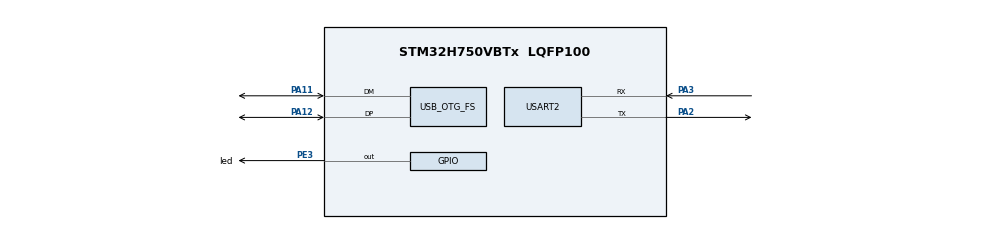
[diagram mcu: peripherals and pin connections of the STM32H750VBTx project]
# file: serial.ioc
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CORTEX_M7.default_mode_Activation=1
Dma.Request0=USART2_RX
Dma.Request1=USART2_TX
Dma.USART2_RX.0.Direction=DMA_PERIPH_TO_MEMORY
Dma.USART2_RX.0.EventEnable=DISABLE
Dma.USART2_RX.0.FIFOMode=DMA_FIFOMODE_DISABLE
Dma.USART2_RX.0.Instance=DMA1_Stream0
Dma.USART2_RX.0.MemDataAlignment=DMA_MDATAALIGN_BYTE
Dma.USART2_RX.0.MemInc=DMA_MINC_ENABLE
Dma.USART2_RX.0.Mode=DMA_NORMAL
Dma.USART2_RX.0.PeriphDataAlignment=DMA_PDATAALIGN_BYTE
Dma.USART2_RX.0.PeriphInc=DMA_PINC_DISABLE
Dma.USART2_RX.0.Polarity=HAL_DMAMUX_REQ_GEN_RISING
Dma.USART2_RX.0.Priority=DMA_PRIORITY_LOW
Dma.USART2_RX.0.RequestNumber=1
Dma.USART2_RX.0.SignalID=NONE
Dma.USART2_RX.0.SyncEnable=DISABLE
Dma.USART2_RX.0.SyncPolarity=HAL_DMAMUX_SYNC_NO_EVENT
Dma.USART2_RX.0.SyncRequestNumber=1
Dma.USART2_RX.0.SyncSignalID=NONE
Dma.USART2_TX.1.Direction=DMA_MEMORY_TO_PERIPH
Dma.USART2_TX.1.EventEnable=DISABLE
Dma.USART2_TX.1.FIFOMode=DMA_FIFOMODE_DISABLE
Dma.USART2_TX.1.Instance=DMA1_Stream1
Dma.USART2_TX.1.MemDataAlignment=DMA_MDATAALIGN_BYTE
Dma.USART2_TX.1.MemInc=DMA_MINC_ENABLE
Dma.USART2_TX.1.Mode=DMA_NORMAL
Dma.USART2_TX.1.PeriphDataAlignment=DMA_PDATAALIGN_BYTE
Dma.USART2_TX.1.PeriphInc=DMA_PINC_DISABLE
Dma.USART2_TX.1.Polarity=HAL_DMAMUX_REQ_GEN_RISING
Dma.USART2_TX.1.Priority=DMA_PRIORITY_LOW
Dma.USART2_TX.1.RequestNumber=1
Dma.USART2_TX.1.SignalID=NONE
Dma.USART2_TX.1.SyncEnable=DISABLE
Dma.USART2_TX.1.SyncPolarity=HAL_DMAMUX_SYNC_NO_EVENT
Dma.USART2_TX.1.SyncRequestNumber=1
Dma.USART2_TX.1.SyncSignalID=NONE
Mcu.Family=STM32H7
Mcu.Name=STM32H750VBTx
Mcu.Package=LQFP100
NVIC.DMA1_Stream0_IRQn=true\:0\:0\:false\:false\:true\:false\:true\:true
NVIC.DMA1_Stream1_IRQn=true\:0\:0\:false\:false\:true\:false\:true\:true
NVIC.OTG_FS_IRQn=true\:0\:0\:false\:false\:true\:false\:true\:true
NVIC.PriorityGroup=NVIC_PRIORITYGROUP_4
NVIC.USART2_IRQn=true\:0\:0\:false\:false\:true\:true\:true\:true
PA11.Mode=Device_Only
PA11.Signal=USB_OTG_FS_DM
PA12.Mode=Device_Only
PA12.Signal=USB_OTG_FS_DP
PA2.Mode=Asynchronous
PA2.Signal=USART2_TX
PA3.Mode=Asynchronous
PA3.Signal=USART2_RX
PE3.GPIO_Label=led
PE3.PinState=GPIO_PIN_SET
PE3.Signal=GPIO_Output
PH0-OSC_IN\ (PH0).Mode=HSE-External-Oscillator
PH0-OSC_IN\ (PH0).Signal=RCC_OSC_IN
PH1-OSC_OUT\ (PH1).Mode=HSE-External-Oscillator
PH1-OSC_OUT\ (PH1).Signal=RCC_OSC_OUT
ProjectManager.HeapSize=0x200
ProjectManager.StackSize=0x400
ProjectManager.TargetToolchain=STM32CubeIDE
RCC.ADCFreq_Value=50390625
RCC.APB1Freq_Value=120000000
RCC.APB2Freq_Value=120000000
RCC.APB3Freq_Value=120000000
RCC.APB4Freq_Value=120000000
RCC.CortexFreq_Value=120000000
RCC.DIVM1=5
RCC.DIVN1=48
RCC.HCLKFreq_Value=120000000
RCC.PLL2FRACN=0
RCC.PLL3FRACN=0
RCC.PLLFRACN=0
RCC.PLLSourceVirtual=RCC_PLLSOURCE_HSE
RCC.SYSCLKFreq_VALUE=120000000
RCC.SYSCLKSource=RCC_SYSCLKSOURCE_PLLCLK
RCC.USART234578CLockSelection=RCC_USART234578CLKSOURCE_CSI
RCC.USBCLockSelection=RCC_USBCLKSOURCE_HSI48
RCC.USBFreq_Value=48000000
USART2.VirtualMode-Asynchronous=VM_ASYNC
USB_DEVICE.CLASS_NAME_FS=CDC
USB_DEVICE.VirtualMode-CDC_FS=Cdc
USB_DEVICE.VirtualModeFS=Cdc_FS
USB_OTG_FS.VirtualMode=Device_Only
VP_MEMORYMAP_VS_MEMORYMAP.Mode=CurAppReg
VP_USB_DEVICE_VS_USB_DEVICE_CDC_FS.Mode=CDC_FS
board=custom

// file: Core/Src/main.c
/* USER CODE BEGIN Header */
/**
  ******************************************************************************
  * @file           : main.c
  * @brief          : Main program body
  ******************************************************************************
  * @attention
  *
  * Copyright (c) 2025 STMicroelectronics.
  * All rights reserved.
  *
  * This software is licensed under terms that can be found in the LICENSE file
  * in the root directory of this software component.
  * If no LICENSE file comes with this software, it is provided AS-IS.
  *
  ******************************************************************************
  */
/* USER CODE END Header */
#include "main.h"
#include "usb_device.h"

/* USER CODE BEGIN Includes */
#include "usbd_cdc_if.h"
//#include "usb_com.h"
/* USER CODE END Includes */

/* USER CODE BEGIN PD */
//RxDef USB_COM;
/* USER CODE END PD */

UART_HandleTypeDef huart2;
DMA_HandleTypeDef hdma_usart2_rx;
DMA_HandleTypeDef hdma_usart2_tx;

/* USER CODE BEGIN PV */
//uint8_t rx_data[256] = {0};
//unsigned char buff[10]={"Abed"};
//extern uint8_t UserTxBufferFS[APP_TX_DATA_SIZE];
//extern uint8_t UserRxBufferFS[APP_TX_DATA_SIZE];
//void HAL_UARTEx_RxEventCallback(UART_HandleTypeDef *huart, uint16_t Size)
//{
//    if (huart->Instance == USART2)
//    {
//        // 使用DMA将接收到的数据发送回去
//        HAL_UART_Transmit_DMA(&huart2, rx_data, Size);
//        // 重新启动接收，使用Ex函数，接收不定长数据
//        HAL_UARTEx_ReceiveToIdle_DMA(&huart2, rx_data, sizeof(rx_data));
//        // 关闭DMA传输过半中断（HAL库默认开启，但我们只需要接收完成中断）
//        __HAL_DMA_DISABLE_IT(huart2.hdmarx, DMA_IT_HT);
//        if(Size >= 2) // 至少需要2字节指令
//                {
//                    // 判断是否收到ON指令（注意：指令需以字符串形式发送，如末尾带\r\n）
//                    if(strncmp((char*)rx_data, "ON", 2) == 0)
//                    {
//                        HAL_GPIO_WritePin(led_GPIO_Port, led_Pin, GPIO_PIN_SET); // 开灯
//                    }
//                    // 判断是否收到OFF指令（建议发送"OFF"后跟终止符）
//                    else if(strncmp((char*)rx_data, "OFF", 3) == 0)
//                    {
//                        HAL_GPIO_WritePin(led_GPIO_Port, led_Pin, GPIO_PIN_RESET); // 关灯
//                    }
//                }
//    }
//}
/* USER CODE END PV */

void SystemClock_Config(void);
static void MPU_Config(void);
static void MX_GPIO_Init(void);
static void MX_DMA_Init(void);
static void MX_USART2_UART_Init(void);

/* USER CODE BEGIN 0 */
//void UART_Init()
//{
//    HAL_UARTEx_ReceiveToIdle_DMA(&huart2, rx_data, sizeof(rx_data));
//    __HAL_DMA_DISABLE_IT(huart2.hdmarx, DMA_IT_HT);
//}
/* USER CODE END 0 */

int main(void)
{

  /* MPU Configuration--------------------------------------------------------*/
  MPU_Config();

  /* MCU Configuration--------------------------------------------------------*/

  /* Reset of all peripherals, Initializes the Flash interface and the Systick. */
  HAL_Init();

  /* Configure the system clock */
  SystemClock_Config();

  /* Initialize all configured peripherals */
  MX_GPIO_Init();
  MX_DMA_Init();
  MX_USART2_UART_Init();
  MX_USB_DEVICE_Init();
  /* USER CODE BEGIN 2 */
//  HAL_UARTEx_ReceiveToIdle_DMA(&huart2, rx_data, sizeof(rx_data));
//  __HAL_DMA_DISABLE_IT(huart2.hdmarx, DMA_IT_HT);
//  UART_Init();
  /* USER CODE END 2 */

  /* Infinite loop */
  while (1)
  {

  }
}

void SystemClock_Config(void)
{
  RCC_OscInitTypeDef RCC_OscInitStruct = {0};
  RCC_ClkInitTypeDef RCC_ClkInitStruct = {0};

  /** Supply configuration update enable
  */
  HAL_PWREx_ConfigSupply(PWR_LDO_SUPPLY);

  /** Configure the main internal regulator output voltage
  */
  __HAL_PWR_VOLTAGESCALING_CONFIG(PWR_REGULATOR_VOLTAGE_SCALE3);

  while(!__HAL_PWR_GET_FLAG(PWR_FLAG_VOSRDY)) {}

  /** Initializes the RCC Oscillators according to the specified parameters
  * in the RCC_OscInitTypeDef structure.
  */
  RCC_OscInitStruct.OscillatorType = RCC_OSCILLATORTYPE_HSI48|RCC_OSCILLATORTYPE_CSI
                              |RCC_OSCILLATORTYPE_HSE;
  RCC_OscInitStruct.HSEState = RCC_HSE_ON;
  RCC_OscInitStruct.HSI48State = RCC_HSI48_ON;
  RCC_OscInitStruct.CSIState = RCC_CSI_ON;
  RCC_OscInitStruct.CSICalibrationValue = RCC_CSICALIBRATION_DEFAULT;
  RCC_OscInitStruct.PLL.PLLState = RCC_PLL_ON;
  RCC_OscInitStruct.PLL.PLLSource = RCC_PLLSOURCE_HSE;
  RCC_OscInitStruct.PLL.PLLM = 5;
  RCC_OscInitStruct.PLL.PLLN = 48;
  RCC_OscInitStruct.PLL.PLLP = 2;
  RCC_OscInitStruct.PLL.PLLQ = 2;
  RCC_OscInitStruct.PLL.PLLR = 2;
  RCC_OscInitStruct.PLL.PLLRGE = RCC_PLL1VCIRANGE_2;
  RCC_OscInitStruct.PLL.PLLVCOSEL = RCC_PLL1VCOWIDE;
  RCC_OscInitStruct.PLL.PLLFRACN = 0;
  if (HAL_RCC_OscConfig(&RCC_OscInitStruct) != HAL_OK)
  {
    Error_Handler();
  }

  /** Initializes the CPU, AHB and APB buses clocks
  */
  RCC_ClkInitStruct.ClockType = RCC_CLOCKTYPE_HCLK|RCC_CLOCKTYPE_SYSCLK
                              |RCC_CLOCKTYPE_PCLK1|RCC_CLOCKTYPE_PCLK2
                              |RCC_CLOCKTYPE_D3PCLK1|RCC_CLOCKTYPE_D1PCLK1;
  RCC_ClkInitStruct.SYSCLKSource = RCC_SYSCLKSOURCE_PLLCLK;
  RCC_ClkInitStruct.SYSCLKDivider = RCC_SYSCLK_DIV1;
  RCC_ClkInitStruct.AHBCLKDivider = RCC_HCLK_DIV1;
  RCC_ClkInitStruct.APB3CLKDivider = RCC_APB3_DIV1;
  RCC_ClkInitStruct.APB1CLKDivider = RCC_APB1_DIV1;
  RCC_ClkInitStruct.APB2CLKDivider = RCC_APB2_DIV1;
  RCC_ClkInitStruct.APB4CLKDivider = RCC_APB4_DIV1;

  if (HAL_RCC_ClockConfig(&RCC_ClkInitStruct, FLASH_LATENCY_2) != HAL_OK)
  {
    Error_Handler();
  }
}

static void MX_USART2_UART_Init(void)
{

  huart2.Instance = USART2;
  huart2.Init.BaudRate = 115200;
  huart2.Init.WordLength = UART_WORDLENGTH_8B;
  huart2.Init.StopBits = UART_STOPBITS_1;
  huart2.Init.Parity = UART_PARITY_NONE;
  huart2.Init.Mode = UART_MODE_TX_RX;
  huart2.Init.HwFlowCtl = UART_HWCONTROL_NONE;
  huart2.Init.OverSampling = UART_OVERSAMPLING_16;
  huart2.Init.OneBitSampling = UART_ONE_BIT_SAMPLE_DISABLE;
  huart2.Init.ClockPrescaler = UART_PRESCALER_DIV1;
  huart2.AdvancedInit.AdvFeatureInit = UART_ADVFEATURE_NO_INIT;
  if (HAL_UART_Init(&huart2) != HAL_OK)
  {
    Error_Handler();
  }
  if (HAL_UARTEx_SetTxFifoThreshold(&huart2, UART_TXFIFO_THRESHOLD_1_8) != HAL_OK)
  {
    Error_Handler();
  }
  if (HAL_UARTEx_SetRxFifoThreshold(&huart2, UART_RXFIFO_THRESHOLD_1_8) != HAL_OK)
  {
    Error_Handler();
  }
  if (HAL_UARTEx_DisableFifoMode(&huart2) != HAL_OK)
  {
    Error_Handler();
  }

}

static void MX_DMA_Init(void)
{

  /* DMA controller clock enable */
  __HAL_RCC_DMA1_CLK_ENABLE();

  /* DMA interrupt init */
  /* DMA1_Stream0_IRQn interrupt configuration */
  HAL_NVIC_SetPriority(DMA1_Stream0_IRQn, 0, 0);
  HAL_NVIC_EnableIRQ(DMA1_Stream0_IRQn);
  /* DMA1_Stream1_IRQn interrupt configuration */
  HAL_NVIC_SetPriority(DMA1_Stream1_IRQn, 0, 0);
  HAL_NVIC_EnableIRQ(DMA1_Stream1_IRQn);

}

static void MX_GPIO_Init(void)
{
  GPIO_InitTypeDef GPIO_InitStruct = {0};

  /* GPIO Ports Clock Enable */
  __HAL_RCC_GPIOE_CLK_ENABLE();
  __HAL_RCC_GPIOH_CLK_ENABLE();
  __HAL_RCC_GPIOA_CLK_ENABLE();

  /*Configure GPIO pin Output Level */
  HAL_GPIO_WritePin(led_GPIO_Port, led_Pin, GPIO_PIN_SET);

  /*Configure GPIO pin : led_Pin */
  GPIO_InitStruct.Pin = led_Pin;
  GPIO_InitStruct.Mode = GPIO_MODE_OUTPUT_PP;
  GPIO_InitStruct.Pull = GPIO_NOPULL;
  GPIO_InitStruct.Speed = GPIO_SPEED_FREQ_LOW;
  HAL_GPIO_Init(led_GPIO_Port, &GPIO_InitStruct);

}

 /* MPU Configuration */

void MPU_Config(void)
{
  MPU_Region_InitTypeDef MPU_InitStruct = {0};

  /* Disables the MPU */
  HAL_MPU_Disable();

  /** Initializes and configures the Region and the memory to be protected
  */
  MPU_InitStruct.Enable = MPU_REGION_ENABLE;
  MPU_InitStruct.Number = MPU_REGION_NUMBER0;
  MPU_InitStruct.BaseAddress = 0x0;
  MPU_InitStruct.Size = MPU_REGION_SIZE_4GB;
  MPU_InitStruct.SubRegionDisable = 0x87;
  MPU_InitStruct.TypeExtField = MPU_TEX_LEVEL0;
  MPU_InitStruct.AccessPermission = MPU_REGION_NO_ACCESS;
  MPU_InitStruct.DisableExec = MPU_INSTRUCTION_ACCESS_DISABLE;
  MPU_InitStruct.IsShareable = MPU_ACCESS_SHAREABLE;
  MPU_InitStruct.IsCacheable = MPU_ACCESS_NOT_CACHEABLE;
  MPU_InitStruct.IsBufferable = MPU_ACCESS_NOT_BUFFERABLE;

  HAL_MPU_ConfigRegion(&MPU_InitStruct);
  /* Enables the MPU */
  HAL_MPU_Enable(MPU_PRIVILEGED_DEFAULT);

}

void Error_Handler(void)
{
  __disable_irq();
  while (1)
  {
  }
}
